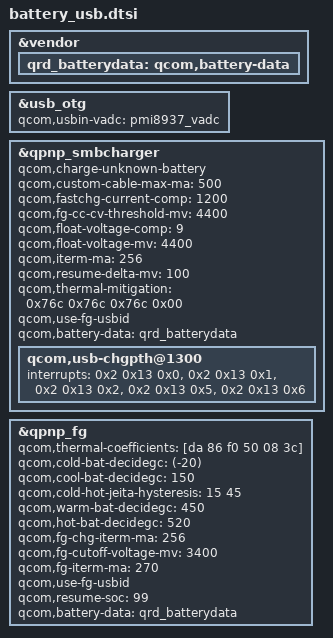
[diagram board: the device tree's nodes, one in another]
&vendor {
	qrd_batterydata: qcom,battery-data {
        #include "batterydata/Huaqin_A609x_7000mAh_averaged_MasterSlave.dtsi"
		#include "batterydata/Huaqin_A609x_7000mAh_averaged_SecondSlave.dtsi"
	};
};

&usb_otg {
	qcom,usbin-vadc = <&pmi8937_vadc>;
};

&qpnp_smbcharger {
    qcom,charge-unknown-battery;
	qcom,custom-cable-max-ma = <500>;
	qcom,fastchg-current-comp = <1200>;
	qcom,fg-cc-cv-threshold-mv = <4400>;
	qcom,float-voltage-comp = <9>;
	qcom,float-voltage-mv = <4400>;
	qcom,iterm-ma = <256>;
	qcom,resume-delta-mv = <100>;
	qcom,thermal-mitigation = <0x76c 0x76c 0x76c 0x00>;
	qcom,use-fg-usbid;

    qcom,battery-data = <&qrd_batterydata>;

	/delete-property/ qcom,parallel-allowed-lowering-ma;
	/delete-property/ qcom,parallel-usb-9v-min-current-ma;
	/delete-property/ qcom,parallel-usb-min-current-ma;
	/delete-property/ qcom,autoadjust-vfloat;

	qcom,usb-chgpth@1300 {
		interrupt-names = "usbin-uv", "usbin-ov", "usbin-src-det", "aicl-done", "usbid-change";
		interrupts =	<0x2 0x13 0x0>,
				<0x2 0x13 0x1>,
				<0x2 0x13 0x2>,
				<0x2 0x13 0x5>,
				<0x2 0x13 0x6>;
	};
};

&qpnp_fg {
	qcom,thermal-coefficients = [da 86 f0 50 08 3c];
	qcom,cold-bat-decidegc = <(-20)>;
	qcom,cool-bat-decidegc = <150>;
	qcom,cold-hot-jeita-hysteresis = <15 45>;
	qcom,warm-bat-decidegc = <450>;
	qcom,hot-bat-decidegc = <520>;

	qcom,fg-chg-iterm-ma = <256>;
	qcom,fg-cutoff-voltage-mv = <3400>;
	qcom,fg-iterm-ma = <270>;
	qcom,use-fg-usbid;
	qcom,resume-soc = <99>;

    qcom,battery-data = <&qrd_batterydata>;
};
